# K1921VG1T register map
Vendor: NIIET; Series: K1921VGx; File version: 2.8
CPU: other r0p1, little endian, MPU, FPU, 4 interrupt priority bits
Registers are 32-bit, read-write, reset 0x0 unless marked. A register's access mark holds for its fields unless they carry their own. Offsets are from the block's base; [hi:lo] are bit positions; {n}, {i} and the like mark numbered series; 'fields as' and 'values as' point back to an identical list.

## PWM0 — PWM control registers
Base 0x5000D000
Same registers: PWM{n} {0x5000D000+0x1000*n} (n=1..15)
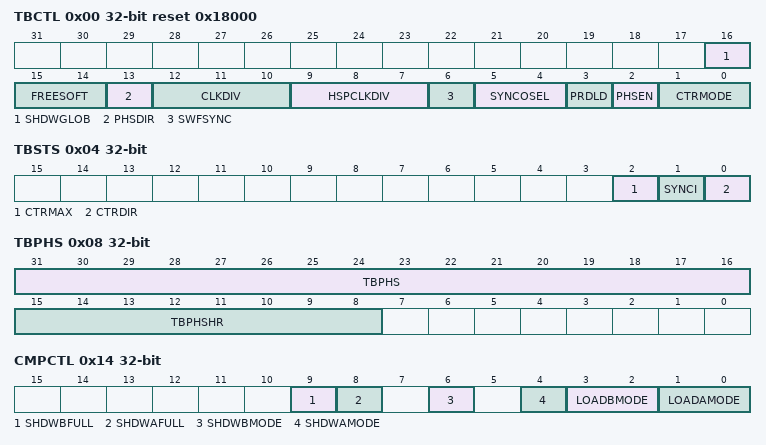
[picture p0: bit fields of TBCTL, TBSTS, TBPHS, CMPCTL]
0x00 TBCTL reset 0x18000 — Time-Base Control Register
  [16] SHDWGLOB — Global enabe for all shadow loads
  [15:14] FREESOFT — Emulation mode bits - select the behavior of the time-base counter during emulation events
    0=StopAtTBCLK (stop timer at next TBCLK tact); 1=StopAtPeriod (stop timer when period ends); 2=free run mode
  [13] PHSDIR — Phase direction bit
  [12:10] CLKDIV — Time-base clock prescale bits
    0=Div1 (clock not divided); 1=Div2 (clock divided by 2); 2=Div4 (clock divided by 4); 3=Div8 (clock divided by 8); 4=Div16 (clock divided by 16); 5=Div32 (clock divided by 32); 6=Div64 (clock divided by 64); 7=Div128 (clock divided by 128)
  [9:7] HSPCLKDIV — High speed time-base clock prescale bits
    0=Div1 (clock not divided); 1=Div2 (clock divided by 2); 2=Div4 (clock divided by 4); 3=Div6 (clock divided by 6); 4=Div8 (clock divided by 8); 5=Div10 (clock divided by 10); 6=Div12 (clock divided by 12); 7=Div14 (clock divided by 14)
  [6] SWFSYNC — Software forced synchronization pulse
  [5:4] SYNCOSEL — Synchronization Output Select. These bits select the source of the PWM_SYNCO signal.
    0=SYNCI (PWM_SYNCI is source for PWM_SYNCO); 1=CTREqZero (CTR = 0000h is source for PWM_SYNCO); 2=CTREqCMPB (CTR = CMPB is source for PWM_SYNCO); 3=Disable (PWM_SYNCO generation disabled)
  [3] PRDLD — Active period register load from shadow register select
  [2] PHSEN — Counter register load from phase register enable
  [1:0] CTRMODE — Counter mode
    0=Up (count direction up); 1=Down (count direction down); 2=UpDown (count direction up-down); 3=Stop (counter stopped)
0x04 TBSTS — Time-Base Status Register
  [2] CTRMAX — Time-Base counter max latched status bit
  [1] SYNCI — Input synchronization latched status bit
  [0] CTRDIR ro — Time-Base counter direction status bit
0x08 TBPHS — Time-Base Phase Register
  [31:16] TBPHS — Time-base counter phase
  [15:8] TBPHSHR — Time-base counter phase in High-Resolution mode
0x0C TBCTR — Time-Base Counter Register
  [15:0] VAL — Current time-base counter value
0x10 TBPRD — Time-Base Period Register
  [15:0] VAL — Period of the time-base counter
0x14 CMPCTL — Counter-Compare Control Register
  [9] SHDWBFULL ro — CMPB shadow register full status flag
  [8] SHDWAFULL ro — CMPA shadow register full status flag
  [6] SHDWBMODE — CMPB register operating mode
  [4] SHDWAMODE — CMPA register operating mode
  [3:2] LOADBMODE — Active CMPB load from shadow select mode
    0=CTREqZero (shadow load for CMPx (x=A,B) when CTR = 0); 1=CTREqPRD (shadow load for CMPx (x=A,B) when CTR = PRD); 2=CTREqZeroPRD (shadow load for CMPx (x=A,B) when CTR = 0 or CTR = PRD); 3=Disable (shadow load for CMPx (x=A,B) disabled)
  [1:0] LOADAMODE — Active CMPA load from shadow select mode
    values as LOADBMODE
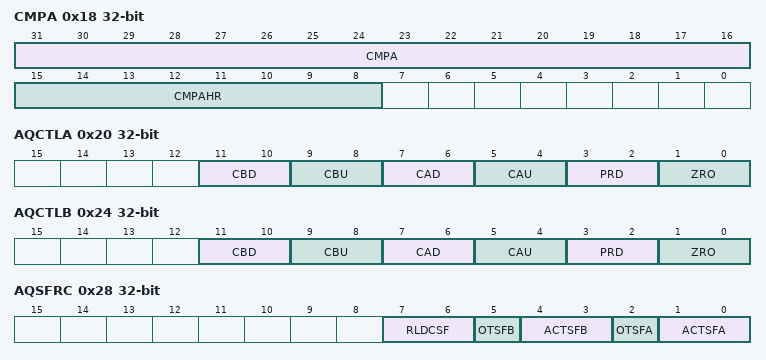
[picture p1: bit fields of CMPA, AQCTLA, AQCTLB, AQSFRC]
0x18 CMPA — Counter-Compare A Register
  [31:16] CMPA — The value compared to the time-base counter (TBCTR)
  [15:8] CMPAHR — The value compared to the time-base counter (TBCTR) in High-Resolution mode
0x1C CMPB — Counter-Compare B Register
  [31:16] CMPB — The value compared to the time-base counter (TBCTR)
0x20 AQCTLA — Action-Qualifier Output A Control Register
  [all] fields
    0=NoAction; 1=clear PWMA/PWMB; 2=Set (set PWMA/PWMB); 3=Toggle (inverse PWMA/PWMB)
  [11:10] CBD — Action when the time-base counter equals the active CMPB register and the counter is decrementing
  [9:8] CBU — Action when the counter equals the active CMPB register and the counter is incrementing
  [7:6] CAD — Action when the counter equals the active CMPA register and the counter is decrementing
  [5:4] CAU — Action when the counter equals the active CMPA register and the counter is incrementing
  [3:2] PRD — Action when the counter equals the period
  [1:0] ZRO — Action when counter equals zero
0x24 AQCTLB — Action-Qualifier Output B Control Register
  fields as AQCTLA
0x28 AQSFRC — Action-Qualifier Software Force Register
  [7:6] RLDCSF — AQCSFRC active register reload from shadow options
    0=CTREqZero (load when CTR = 0); 1=CTREqPRD (load when CTR = PRD); 2=CTREqZeroPRD (load when CTR = 0 or CTR = PRD); 3=NoShadow (load immediatelly)
  [5] OTSFB — One-time software forced event on output B
  [4:3] ACTSFB — Action when one-time software force B is invoked
    values as the fields of AQCTLA
  [2] OTSFA — One-time software forced event on output A
  [1:0] ACTSFA — Action when one-time software force A is invoked
    values as the fields of AQCTLA
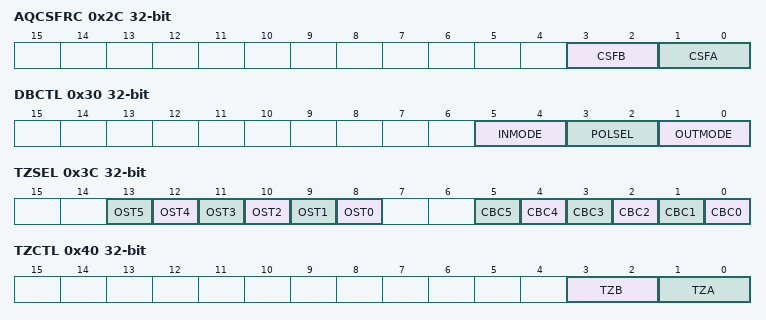
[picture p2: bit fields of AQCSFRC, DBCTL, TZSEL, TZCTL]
0x2C AQCSFRC — Action-Qualifier Continuous Software Force Register
  [3:2] CSFB — Continuous software force on output B
    0=NoAction; 1=clear PWMA/PWMB; 2=Set (set PWMA/PWMB)
  [1:0] CSFA — Continuous software force on output A
    0=NoAction; 1=clear PWMA/PWMB; 2=Set (set PWMA/PWMB)
0x30 DBCTL — Dead-Band Generator Control Register
  [5:4] INMODE — Dead band input mode control
    0=APosNeg (PWMA is used for posedge and negedge control); 1=ANeg_BPos (PWMA is used for negedge and PWMB is used for posedge control); 2=APos_BNeg (PWMA is used for posedge and PWMB is used for negedge control); 3=BPosNeg (PWMB is used for posedge and negedge control)
  [3:2] POLSEL — Polarity select control
    0=InvDisable (inverse disabled); 1=InvA (inverse on PWMA); 2=InvB (inverse on PWMB); 3=InvAB (inverse on PWMA and PWMB)
  [1:0] OUTMODE — Dead-band output mode control
    0=NoSpec (edge for deadtime is no specified); 1=BNeg (deadtime on PWMB negedge); 2=APos (deadtime on PWMA posedge); 3=Apos_BNeg (deadtime on PWMA posedge and PWMB negedge)
0x34 DBRED — Dead-Band Generator Rising Edge Delay Register
  [9:0] DEL — Rising edge delay count
0x38 DBFED — Dead-Band Generator Falling Edge Delay Register
  [9:0] DEL — Falling edge delay count
0x3C TZSEL — Trip-Zone Select Register
  [n+8] OST{n} (n=0..5) — One-Shot trip-zone {n} enable
  [n] CBC{n} (n=0..5) — Cycle-by-Cycle trip-zone {n} enable
0x40 TZCTL — Trip-Zone Control Register
  [3:2] TZB — When a trip event occurs the following action is taken on output B
    0=Z (PWMA/PWMB go to Z on failture); 1=Set (PWMA/PWMB go to 1 on failture); 2=Clear (PWMA/PWMB go to 0 on failture); 3=no action on failture
  [1:0] TZA — When a trip event occurs the following action is taken on output A
    values as TZB
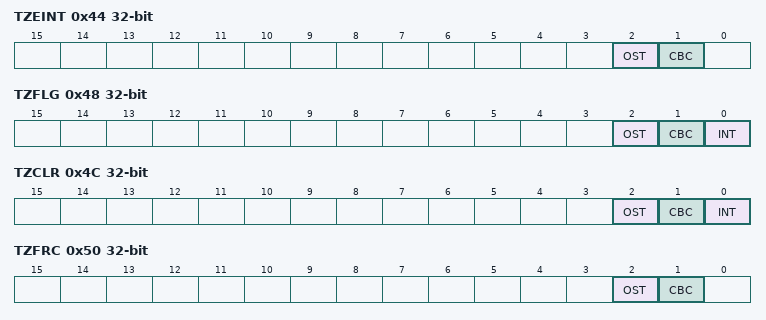
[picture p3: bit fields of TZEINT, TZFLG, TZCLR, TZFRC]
0x44 TZEINT — Trip-Zone Enable Interrupt Register
  [2] OST — Trip-zone One-Shot interrupt enable
  [1] CBC — Trip-zone Cycle-by-Cycle interrupt enable
0x48 TZFLG ro — Trip-Zone Flag Register
  [2] OST — Latched status flag for a One-Shot trip event
  [1] CBC — Latched status flag for Cycle-By-Cycle trip event
  [0] INT — Latched trip interrupt status flag
0x4C TZCLR wo — Trip-Zone Clear Register
  [2] OST — Clear flag for One-Shot trip latch
  [1] CBC — Clear flag for Cycle-By-Cycle trip latch
  [0] INT — Clear trip-zone interrupt flag
0x50 TZFRC wo — Trip-Zone Force Register
  [2] OST — Force a One-Shot trip event via software
  [1] CBC — Force a Cycle-by-Cycle trip event via software
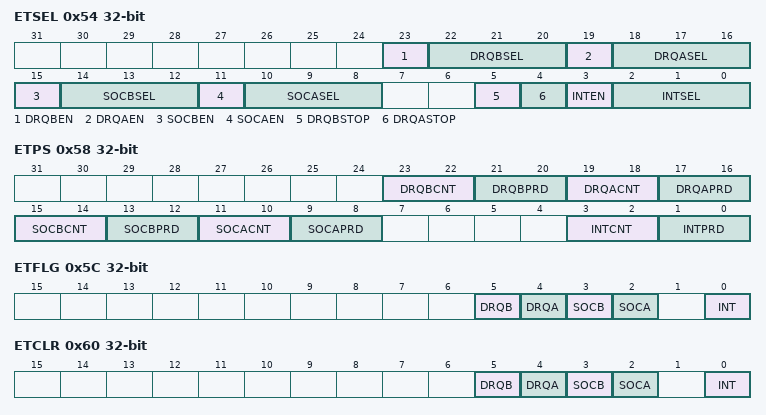
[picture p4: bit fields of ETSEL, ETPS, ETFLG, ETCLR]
0x54 ETSEL — Event-Trigger Selection Register
  [23] DRQBEN — Enable the DMA request from PWM B (RX)
  [22:20] DRQBSEL — PWM B DMA request event selection
    0=CTREqCMPA (generate PWM_SOCA/PWM_SOCB/PWN_INT impulse on CTR = CMPA); 1=CTREqZero (generate PWM_SOCA/PWM_SOCB/PWN_INT impulse on CTR = 0); 2=CTREqPRD (generate PWM_SOCA/PWM_SOCB/PWN_INT impulse on CTR = PRD); 3=CTREqCMPB (generate PWM_SOCA/PWM_SOCB/PWN_INT impulse on CTR = CMPB); 4=CTREqCMPA_OnUp (generate PWM_SOCA/PWM_SOCB/PWN_INT impulse on CTR = CMPA when count up); 5=CTREqCMPA_OnDown (generate PWM_SOCA/PWM_SOCB/PWN_INT impulse on CTR = CMPA when count down); 6=CTREqCMPB_OnUp (generate PWM_SOCA/PWM_SOCB/PWN_INT impulse on CTR = CMPB when count up); 7=CTREqCMPB_OnDown (generate PWM_SOCA/PWM_SOCB/PWN_INT impulse on CTR = CMPB when count down)
  [19] DRQAEN — Enable the DMA request from PWM A (TX)
  [18:16] DRQASEL — PWM A DMA request event selection
    values as DRQBSEL
  [15] SOCBEN — Enable the ADC start of conversion B PWM_SOCB pulse
  [14:12] SOCBSEL — PWM_SOCB selection Options
    values as DRQBSEL
  [11] SOCAEN — Enable the ADC start of conversion A PWM_SOCA pulse
  [10:8] SOCASEL — PWM_SOCA selection Options
    values as DRQBSEL
  [5] DRQBSTOP — Automatic clear DMA RX request (PWM B) generation when channel ends all transactions
  [4] DRQASTOP — Automatic clear DMA TX request (PWM A) generation when channel ends all transactions
  [3] INTEN — Enable PWM_INT interrupt generation
  [2:0] INTSEL — PWM_INT interrupt selection options
    values as DRQBSEL
0x58 ETPS — Event-Trigger Prescale Register
  [23:22] DRQBCNT ro — PWM DMA request event B counter
  [21:20] DRQBPRD — PWM DMA request B period select
  [19:18] DRQACNT ro — PWM DMA request event A counter
  [17:16] DRQAPRD — PWM DMA request A period select
  [15:14] SOCBCNT ro — PWM ADC Start-of-Conversion B event (PWM_SOCB) counter register
  [13:12] SOCBPRD — PWM ADC Start-of-Conversion B event (PWM_SOCB) period select
  [11:10] SOCACNT ro — PWM ADC Start-of-Conversion A event (PWM_SOCA) counter register
  [9:8] SOCAPRD — PWM ADC Start-of-Conversion A event (PWM_SOCA) period select
  [3:2] INTCNT ro — PWM interrupt event (PWM_INT) counter register
  [1:0] INTPRD — PWM interrupt (PWM_INT) period select
0x5C ETFLG ro — Event-Trigger Flag Register
  [5] DRQB — Latched PWM DMA request B status flag
  [4] DRQA — Latched PWM DMA request A status flag
  [3] SOCB — Latched PWM ADC Start-of-Conversion B (PWM_SOCB) status flag
  [2] SOCA — Latched PWM ADC Start-of-Conversion A (PWM_SOCA) status flag
  [0] INT — Latched PWM Interrupt (PWM_INT) status flag
0x60 ETCLR wo — Event-Trigger Clear Register
  [5] DRQB — Latched PWM DMA request B flag clear bit
  [4] DRQA — Latched PWM DMA request A flag clear bit
  [3] SOCB — Latched PWM ADC Start-of-Conversion B (PWM_SOCB) flag clear bit
  [2] SOCA — Latched PWM ADC Start-of-Conversion A (PWM_SOCA) flag clear bit
  [0] INT — Latched PWM Interrupt (PWM_INT) flag clear bit
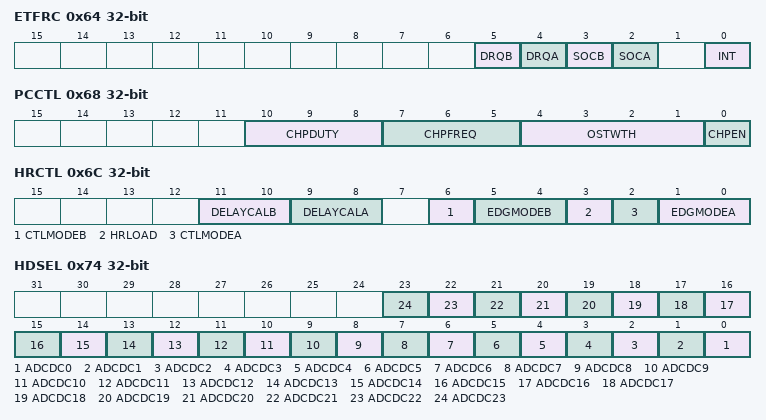
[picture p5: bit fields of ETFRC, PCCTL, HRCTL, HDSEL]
0x64 ETFRC wo — Event-Trigger Force Register
  [5] DRQB — PWM DMA request B force bit
  [4] DRQA — PWM DMA request A force bit
  [3] SOCB — PWM_SOCB force bit
  [2] SOCA — PWM_SOCA force bit
  [0] INT — PWM_INT force bit.
0x68 PCCTL — PWM-Chopper Control Register
  [10:8] CHPDUTY — Chopping clock duty cycle
    {v}=Duty_{v+1}_8 (v=0..6)
  [7:5] CHPFREQ — Chopping clock frequency
    {v}=Div{v+1} (sync frequency divide by {v+1}) (v=0..7)
  [4:1] OSTWTH — One-Shot pulse width
  [0] CHPEN — PWM-chopping enable
0x6C HRCTL — High-Resolution Control Register
  [11:10] DELAYCALB — Delay calibration flags of channel B
  [9:8] DELAYCALA — Delay calibration flags of channel A
  [6] CTLMODEB — Register specifies the delay select on channel B
    0=CMPAHR (delay source in CMPA reg); 1=TBPHSHR (delay source in TBPHS reg)
  [5:4] EDGMODEB — Edge selecting for delay on channel B
    1=posedge will be delayed; 2=negedge will be delayed; 3=BothEdge (posedge and negedge will be delayed)
  [3] HRLOAD — CMPAHR register shadow load mode
    0=CTREqZero (load when CTR = 0); 1=CTREqPRD (load when CTR = PRD)
  [2] CTLMODEA — Register specifies the delay select on channel A
    values as CTLMODEB
  [1:0] EDGMODEA — Edge selecting for delay on channel A
    values as EDGMODEB
0x70 FWDTH — Filter Width select Register
  [7:0] VAL — Pulse filter width selection
0x74 HDSEL — Hold Detector event Select Register 0
  [n] ADCDC{n} (n=0..23) — Hold detector event by ADC Digital Comparator {n} enable
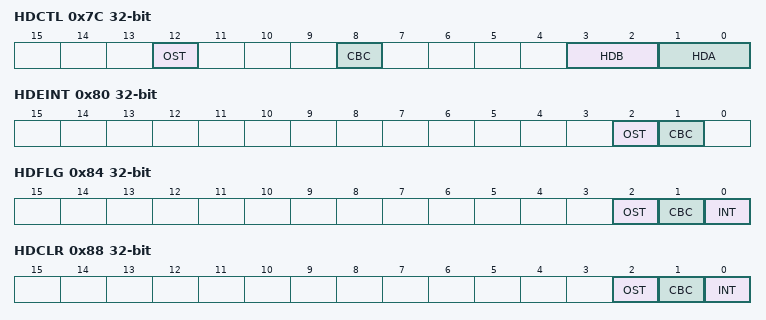
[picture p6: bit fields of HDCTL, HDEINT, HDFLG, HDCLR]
0x7C HDCTL — Hold Detector Control register
  [12] OST — One-Shot hold detector enable
  [8] CBC — Cycle-by-Cycle hold detector enable
  [3:2] HDB — Action when hold detection B is invoked
    1=Set (PWMA/PWMB go to 1 on failture); 2=Clear (PWMA/PWMB go to 0 on failture); 3=no action on failture
  [1:0] HDA — Action when hold detection A is invoked
    values as HDB
0x80 HDEINT — Hold Detector Enable Interrupt Register
  [2] OST — Hold detector One-Shot interrupt enable
  [1] CBC — Hold detector Cycle-by-Cycle interrupt enable
0x84 HDFLG ro — Hold Detector Flag Register
  [2] OST — Latched status flag for hold detector One-Shot event
  [1] CBC — Latched status flag for hold detector Cycle-by-Cycle event
  [0] INT — Latched hold detector interrupt status flag
0x88 HDCLR wo — Register clear HD flag
  [2] OST — Clear flag for One-Shot hold detector latch
  [1] CBC — Clear flag for Cycle-By-Cycle hold detector latch
  [0] INT — Clear hold detector interrupt flag
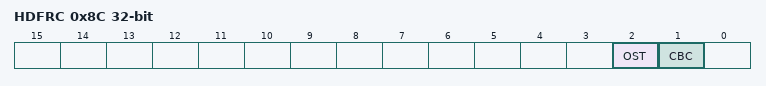
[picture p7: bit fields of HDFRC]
0x8C HDFRC wo — Hold Detector Force Register
  [2] OST — Force a One-Shot hold detector event via software
  [1] CBC — Force a Cycle-by-Cycle hold detector event via software
0x90 HDINTCLR wo — Hold Detector Interrupt pending Clear Register
  [0] INT — Clear HD interrupt pending
0x94 TZINTCLR wo — Trip-Zone Interrupt pending Clear Register
  [0] INT — Clear TZ interrupt pending
0x98 INTCLR wo — PWM Interrupt pending Clear Register
  [0] INT — Clear interrupt pending
